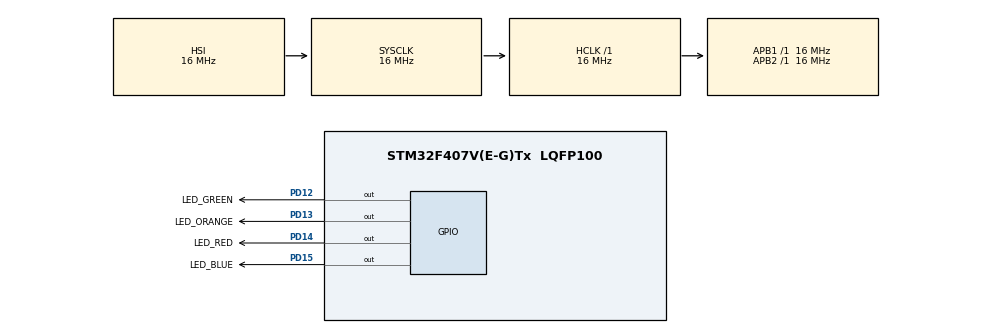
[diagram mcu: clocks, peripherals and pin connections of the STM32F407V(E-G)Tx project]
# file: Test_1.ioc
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Mcu.Family=STM32F4
Mcu.Name=STM32F407V(E-G)Tx
Mcu.Package=LQFP100
NVIC.PriorityGroup=NVIC_PRIORITYGROUP_4
NVIC.TIM1_UP_TIM10_IRQn=true\:0\:0\:false\:false\:true\:true
NVIC.TIM2_IRQn=true\:0\:0\:false\:false\:true\:true
PA13.Mode=Serial_Wire
PA13.Signal=SYS_JTMS-SWDIO
PA14.Mode=Serial_Wire
PA14.Signal=SYS_JTCK-SWCLK
PD12.GPIO_Label=LED_GREEN
PD12.GPIO_Speed=GPIO_SPEED_FREQ_HIGH
PD12.Signal=GPIO_Output
PD13.GPIO_Label=LED_ORANGE
PD13.GPIO_Speed=GPIO_SPEED_FREQ_HIGH
PD13.PinState=GPIO_PIN_RESET
PD13.Signal=GPIO_Output
PD14.GPIO_Label=LED_RED
PD14.GPIO_Speed=GPIO_SPEED_FREQ_HIGH
PD14.Signal=GPIO_Output
PD15.GPIO_Label=LED_BLUE
PD15.GPIO_Speed=GPIO_SPEED_FREQ_HIGH
PD15.Signal=GPIO_Output
PH0-OSC_IN.Mode=HSE-External-Oscillator
PH0-OSC_IN.Signal=RCC_OSC_IN
PH1-OSC_OUT.Mode=HSE-External-Oscillator
PH1-OSC_OUT.Signal=RCC_OSC_OUT
ProjectManager.HeapSize=0x200
ProjectManager.StackSize=0x400
ProjectManager.TargetToolchain=MDK-ARM V5
RCC.AHBFreq_Value=16000000
RCC.APB1Freq_Value=16000000
RCC.APB1TimFreq_Value=16000000
RCC.APB2Freq_Value=16000000
RCC.APB2TimFreq_Value=16000000
RCC.CortexFreq_Value=16000000
RCC.HCLKFreq_Value=16000000
RCC.HSE_VALUE=25000000
RCC.HSI_VALUE=16000000
RCC.LSE_VALUE=32768
RCC.SYSCLKFreq_VALUE=16000000
RCC.VCOOutputFreq_Value=192000000
TIM2.Period=1999
TIM2.Prescaler=7999
VP_TIM1_VS_ClockSourceINT.Mode=Internal
VP_TIM2_VS_ClockSourceINT.Mode=Internal
board=custom

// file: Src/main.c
/* USER CODE BEGIN Header */
/**
  ******************************************************************************
  * @file           : main.c
  * @brief          : Main program body
  ******************************************************************************
  ** This notice applies to any and all portions of this file
  * that are not between comment pairs USER CODE BEGIN and
  * USER CODE END. Other portions of this file, whether
  * inserted by the user or by software development tools
  * are owned by their respective copyright owners.
  *
  * COPYRIGHT(c) 2018 STMicroelectronics
  *
  * Redistribution and use in source and binary forms, with or without modification,
  * are permitted provided that the following conditions are met:
  *   1. Redistributions of source code must retain the above copyright notice,
  *      this list of conditions and the following disclaimer.
  *   2. Redistributions in binary form must reproduce the above copyright notice,
  *      this list of conditions and the following disclaimer in the documentation
  *      and/or other materials provided with the distribution.
  *   3. Neither the name of STMicroelectronics nor the names of its contributors
  *      may be used to endorse or promote products derived from this software
  *      without specific prior written permission.
  *
  * THIS SOFTWARE IS PROVIDED BY THE COPYRIGHT HOLDERS AND CONTRIBUTORS "AS IS"
  * AND ANY EXPRESS OR IMPLIED WARRANTIES, INCLUDING, BUT NOT LIMITED TO, THE
  * IMPLIED WARRANTIES OF MERCHANTABILITY AND FITNESS FOR A PARTICULAR PURPOSE ARE
  * DISCLAIMED. IN NO EVENT SHALL THE COPYRIGHT HOLDER OR CONTRIBUTORS BE LIABLE
  * FOR ANY DIRECT, INDIRECT, INCIDENTAL, SPECIAL, EXEMPLARY, OR CONSEQUENTIAL
  * DAMAGES (INCLUDING, BUT NOT LIMITED TO, PROCUREMENT OF SUBSTITUTE GOODS OR
  * SERVICES; LOSS OF USE, DATA, OR PROFITS; OR BUSINESS INTERRUPTION) HOWEVER
  * CAUSED AND ON ANY THEORY OF LIABILITY, WHETHER IN CONTRACT, STRICT LIABILITY,
  * OR TORT (INCLUDING NEGLIGENCE OR OTHERWISE) ARISING IN ANY WAY OUT OF THE USE
  * OF THIS SOFTWARE, EVEN IF ADVISED OF THE POSSIBILITY OF SUCH DAMAGE.
  *
  ******************************************************************************
  */
/* USER CODE END Header */

#include "main.h"
#include "tim.h"
#include "gpio.h"

void SystemClock_Config(void);

/* USER CODE BEGIN 0 */
int czyZapalona = 0;
/* USER CODE END 0 */

int main(void)
{

  /* MCU Configuration--------------------------------------------------------*/

  /* Reset of all peripherals, Initializes the Flash interface and the Systick. */
  HAL_Init();

  /* Configure the system clock */
  SystemClock_Config();

  /* Initialize all configured peripherals */
  MX_GPIO_Init();
  MX_TIM1_Init();
  MX_TIM2_Init();
  /* USER CODE BEGIN 2 */
	int xyz = 10;
	int zyx = 2;
  /* USER CODE END 2 */

  /* Infinite loop */
  /* USER CODE BEGIN WHILE */
	HAL_GPIO_WritePin(GPIOD, LED_BLUE_Pin, GPIO_PIN_SET);
	HAL_TIM_Base_Start_IT(&htim2);
  while (1)
  {
    /* USER CODE END WHILE */

  }
}

void SystemClock_Config(void)
{
  RCC_OscInitTypeDef RCC_OscInitStruct = {0};
  RCC_ClkInitTypeDef RCC_ClkInitStruct = {0};

  /**Configure the main internal regulator output voltage
  */
  __HAL_RCC_PWR_CLK_ENABLE();
  __HAL_PWR_VOLTAGESCALING_CONFIG(PWR_REGULATOR_VOLTAGE_SCALE1);
  /**Initializes the CPU, AHB and APB busses clocks
  */
  RCC_OscInitStruct.OscillatorType = RCC_OSCILLATORTYPE_HSI;
  RCC_OscInitStruct.HSIState = RCC_HSI_ON;
  RCC_OscInitStruct.HSICalibrationValue = RCC_HSICALIBRATION_DEFAULT;
  RCC_OscInitStruct.PLL.PLLState = RCC_PLL_NONE;
  if (HAL_RCC_OscConfig(&RCC_OscInitStruct) != HAL_OK)
  {
    Error_Handler();
  }
  /**Initializes the CPU, AHB and APB busses clocks
  */
  RCC_ClkInitStruct.ClockType = RCC_CLOCKTYPE_HCLK|RCC_CLOCKTYPE_SYSCLK
                              |RCC_CLOCKTYPE_PCLK1|RCC_CLOCKTYPE_PCLK2;
  RCC_ClkInitStruct.SYSCLKSource = RCC_SYSCLKSOURCE_HSI;
  RCC_ClkInitStruct.AHBCLKDivider = RCC_SYSCLK_DIV1;
  RCC_ClkInitStruct.APB1CLKDivider = RCC_HCLK_DIV1;
  RCC_ClkInitStruct.APB2CLKDivider = RCC_HCLK_DIV1;

  if (HAL_RCC_ClockConfig(&RCC_ClkInitStruct, FLASH_LATENCY_0) != HAL_OK)
  {
    Error_Handler();
  }
}

/* USER CODE BEGIN 4 */
void HAL_TIM_PeriodElapsedCallback(TIM_HandleTypeDef *htim)
{
	if (htim == &htim2)		//obsluga wygaszacza ekranu (uruchamiany po 20s bezczynnosci w trybie MENU GLOWNE)
	{
		if (czyZapalona == 1)
		{
			HAL_GPIO_WritePin(GPIOD, LED_BLUE_Pin, GPIO_PIN_RESET);
			czyZapalona = 0;
		}
		else
		{
			HAL_GPIO_WritePin(GPIOD, LED_BLUE_Pin, GPIO_PIN_SET);
			czyZapalona = 1;
		}
	}
}
/* USER CODE END 4 */

void Error_Handler(void)
{
}

/************************ (C) COPYRIGHT STMicroelectronics *****END OF FILE****/
